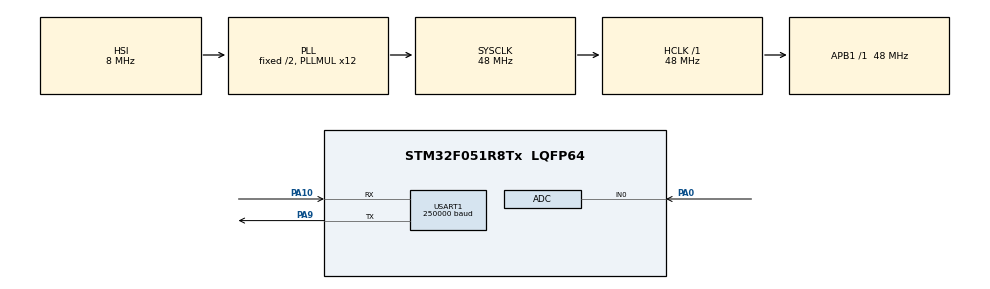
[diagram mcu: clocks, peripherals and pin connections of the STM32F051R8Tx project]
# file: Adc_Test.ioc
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Mcu.Family=STM32F0
Mcu.Name=STM32F051R8Tx
Mcu.Package=LQFP64
PA0.Mode=IN0
PA0.Signal=ADC_IN0
PA10.Mode=Asynchronous
PA10.Signal=USART1_RX
PA9.Mode=Asynchronous
PA9.Signal=USART1_TX
PC14-OSC32_IN.Mode=LSE-External-Oscillator
PC14-OSC32_IN.Signal=RCC_OSC32_IN
PC15-OSC32_OUT.Mode=LSE-External-Oscillator
PC15-OSC32_OUT.Signal=RCC_OSC32_OUT
PF0-OSC_IN.Mode=HSE-External-Oscillator
PF0-OSC_IN.Signal=RCC_OSC_IN
PF1-OSC_OUT.Mode=HSE-External-Oscillator
PF1-OSC_OUT.Signal=RCC_OSC_OUT
ProjectManager.HeapSize=0x200
ProjectManager.StackSize=0x400
ProjectManager.TargetToolchain=STM32CubeIDE
RCC.AHBFreq_Value=48000000
RCC.APB1Freq_Value=48000000
RCC.APB1TimFreq_Value=48000000
RCC.HCLKFreq_Value=48000000
RCC.PLLMUL=RCC_PLL_MUL12
RCC.SYSCLKFreq_VALUE=48000000
RCC.SYSCLKSource=RCC_SYSCLKSOURCE_PLLCLK
USART1.BaudRate=250000
USART1.VirtualMode-Asynchronous=VM_ASYNC
VP_TIM16_VS_ClockSourceINT.Mode=Enable_Timer
board=custom

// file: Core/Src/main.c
/* USER CODE BEGIN Header */
/**
  ******************************************************************************
  * @file           : main.c
  * @brief          : Main program body
  ******************************************************************************
  * @attention
  *
  * Copyright (c) 2023 STMicroelectronics.
  * All rights reserved.
  *
  * This software is licensed under terms that can be found in the LICENSE file
  * in the root directory of this software component.
  * If no LICENSE file comes with this software, it is provided AS-IS.
  *
  ******************************************************************************
  */
/* USER CODE END Header */
#include "main.h"

/* USER CODE BEGIN Includes */
#include <stdio.h>
#include <string.h>
#include "stm32f0xx_hal.h"

/* USER CODE END Includes */

/* USER CODE BEGIN PTD */

uint16_t raw;
char msg[20];
char msg2[15];

volatile uint32_t millis = 0; // Milliseconds counter

#define MAX_READINGS 670 // Maximum number of readings to store

// Structure to store time and ADC value
typedef struct
{
    float time_seconds;
    uint16_t adc_value;
} Reading;

Reading adc_readings[MAX_READINGS]; // Array to store time and ADC readings
uint32_t readings_count = 0; // Number of stored readings

/* USER CODE END PTD */

ADC_HandleTypeDef hadc;

TIM_HandleTypeDef htim16;

UART_HandleTypeDef huart1;

void SystemClock_Config(void);
static void MX_GPIO_Init(void);
static void MX_ADC_Init(void);
static void MX_USART1_UART_Init(void);
static void MX_TIM16_Init(void);

int main(void)
{

  /* MCU Configuration--------------------------------------------------------*/

  /* Reset of all peripherals, Initializes the Flash interface and the Systick. */
  HAL_Init();

  /* Configure the system clock */
  SystemClock_Config();

  /* Initialize all configured peripherals */
  MX_GPIO_Init();
  MX_ADC_Init();
  MX_USART1_UART_Init();
  MX_TIM16_Init();
  /* USER CODE BEGIN 2 */

  HAL_SYSTICK_Config(HAL_RCC_GetHCLKFreq() / 1000); // Configure the SysTick timer for 1ms interrupts

  HAL_TIM_Base_Start_IT(&htim16); // Start TIM16 with interrupts

  /* USER CODE END 2 */

  /* Infinite loop */
  /* USER CODE BEGIN WHILE */
  while (1)
  {

	  // Read ADC value
	  	  	  HAL_ADC_Start(&hadc);
	          HAL_ADC_PollForConversion(&hadc, HAL_MAX_DELAY);
	          uint16_t adc_value = HAL_ADC_GetValue(&hadc);

	          // Calculate time in seconds
	          float time_seconds = (float)(HAL_GetTick()) / 1000.0;

	          // Create a Reading structure and store it in the array
	          if (readings_count < MAX_READINGS)
	          {
	              adc_readings[readings_count].time_seconds = time_seconds;
	              adc_readings[readings_count].adc_value = adc_value;
	              readings_count++;
	          }

	          // Check if we have collected enough readings to transmit
	          if (readings_count >= MAX_READINGS)
	          {
	              // Format and transmit the entire array
	              char uart_data[500]; // Adjust the buffer size as needed
	              int offset = 0;

	              //offset += snprintf(uart_data + offset, sizeof(uart_data) - offset, "Time\tValue\r\n");

	              for (uint32_t i = 0; i < readings_count; i++)
	              {
	                  offset += snprintf(uart_data + offset, sizeof(uart_data) - offset, "%.8f\t%.8f\r\n", adc_readings[i].time_seconds, (float)adc_readings[i].adc_value * 3.3 / 4096.0);
	              }

	              HAL_UART_Transmit(&huart1, (uint8_t *)uart_data, strlen(uart_data), HAL_MAX_DELAY);

	              // Reset the readings_count to collect new readings
	              readings_count = 0;
	          }
    /* USER CODE END WHILE */

  }
}

void SystemClock_Config(void)
{
  RCC_OscInitTypeDef RCC_OscInitStruct = {0};
  RCC_ClkInitTypeDef RCC_ClkInitStruct = {0};
  RCC_PeriphCLKInitTypeDef PeriphClkInit = {0};

  /** Initializes the RCC Oscillators according to the specified parameters
  * in the RCC_OscInitTypeDef structure.
  */
  RCC_OscInitStruct.OscillatorType = RCC_OSCILLATORTYPE_HSI|RCC_OSCILLATORTYPE_HSI14;
  RCC_OscInitStruct.HSIState = RCC_HSI_ON;
  RCC_OscInitStruct.HSI14State = RCC_HSI14_ON;
  RCC_OscInitStruct.HSICalibrationValue = RCC_HSICALIBRATION_DEFAULT;
  RCC_OscInitStruct.HSI14CalibrationValue = 16;
  RCC_OscInitStruct.PLL.PLLState = RCC_PLL_ON;
  RCC_OscInitStruct.PLL.PLLSource = RCC_PLLSOURCE_HSI;
  RCC_OscInitStruct.PLL.PLLMUL = RCC_PLL_MUL12;
  RCC_OscInitStruct.PLL.PREDIV = RCC_PREDIV_DIV1;
  if (HAL_RCC_OscConfig(&RCC_OscInitStruct) != HAL_OK)
  {
    Error_Handler();
  }

  /** Initializes the CPU, AHB and APB buses clocks
  */
  RCC_ClkInitStruct.ClockType = RCC_CLOCKTYPE_HCLK|RCC_CLOCKTYPE_SYSCLK
                              |RCC_CLOCKTYPE_PCLK1;
  RCC_ClkInitStruct.SYSCLKSource = RCC_SYSCLKSOURCE_PLLCLK;
  RCC_ClkInitStruct.AHBCLKDivider = RCC_SYSCLK_DIV1;
  RCC_ClkInitStruct.APB1CLKDivider = RCC_HCLK_DIV1;

  if (HAL_RCC_ClockConfig(&RCC_ClkInitStruct, FLASH_LATENCY_1) != HAL_OK)
  {
    Error_Handler();
  }
  PeriphClkInit.PeriphClockSelection = RCC_PERIPHCLK_USART1;
  PeriphClkInit.Usart1ClockSelection = RCC_USART1CLKSOURCE_PCLK1;
  if (HAL_RCCEx_PeriphCLKConfig(&PeriphClkInit) != HAL_OK)
  {
    Error_Handler();
  }
}

static void MX_ADC_Init(void)
{

  ADC_ChannelConfTypeDef sConfig = {0};

  /** Configure the global features of the ADC (Clock, Resolution, Data Alignment and number of conversion)
  */
  hadc.Instance = ADC1;
  hadc.Init.ClockPrescaler = ADC_CLOCK_ASYNC_DIV1;
  hadc.Init.Resolution = ADC_RESOLUTION_12B;
  hadc.Init.DataAlign = ADC_DATAALIGN_RIGHT;
  hadc.Init.ScanConvMode = ADC_SCAN_DIRECTION_FORWARD;
  hadc.Init.EOCSelection = ADC_EOC_SINGLE_CONV;
  hadc.Init.LowPowerAutoWait = DISABLE;
  hadc.Init.LowPowerAutoPowerOff = DISABLE;
  hadc.Init.ContinuousConvMode = DISABLE;
  hadc.Init.DiscontinuousConvMode = DISABLE;
  hadc.Init.ExternalTrigConv = ADC_SOFTWARE_START;
  hadc.Init.ExternalTrigConvEdge = ADC_EXTERNALTRIGCONVEDGE_NONE;
  hadc.Init.DMAContinuousRequests = DISABLE;
  hadc.Init.Overrun = ADC_OVR_DATA_PRESERVED;
  if (HAL_ADC_Init(&hadc) != HAL_OK)
  {
    Error_Handler();
  }

  /** Configure for the selected ADC regular channel to be converted.
  */
  sConfig.Channel = ADC_CHANNEL_0;
  sConfig.Rank = ADC_RANK_CHANNEL_NUMBER;
  sConfig.SamplingTime = ADC_SAMPLETIME_1CYCLE_5;
  if (HAL_ADC_ConfigChannel(&hadc, &sConfig) != HAL_OK)
  {
    Error_Handler();
  }

}

static void MX_TIM16_Init(void)
{

  htim16.Instance = TIM16;
  htim16.Init.Prescaler = 0;
  htim16.Init.CounterMode = TIM_COUNTERMODE_UP;
  htim16.Init.Period = 65535;
  htim16.Init.ClockDivision = TIM_CLOCKDIVISION_DIV1;
  htim16.Init.RepetitionCounter = 0;
  htim16.Init.AutoReloadPreload = TIM_AUTORELOAD_PRELOAD_DISABLE;
  if (HAL_TIM_Base_Init(&htim16) != HAL_OK)
  {
    Error_Handler();
  }

}

static void MX_USART1_UART_Init(void)
{

  huart1.Instance = USART1;
  huart1.Init.BaudRate = 250000;
  huart1.Init.WordLength = UART_WORDLENGTH_8B;
  huart1.Init.StopBits = UART_STOPBITS_1;
  huart1.Init.Parity = UART_PARITY_NONE;
  huart1.Init.Mode = UART_MODE_TX_RX;
  huart1.Init.HwFlowCtl = UART_HWCONTROL_NONE;
  huart1.Init.OverSampling = UART_OVERSAMPLING_16;
  huart1.Init.OneBitSampling = UART_ONE_BIT_SAMPLE_DISABLE;
  huart1.AdvancedInit.AdvFeatureInit = UART_ADVFEATURE_NO_INIT;
  if (HAL_UART_Init(&huart1) != HAL_OK)
  {
    Error_Handler();
  }

}

static void MX_GPIO_Init(void)
{

  /* GPIO Ports Clock Enable */
  __HAL_RCC_GPIOC_CLK_ENABLE();
  __HAL_RCC_GPIOF_CLK_ENABLE();
  __HAL_RCC_GPIOA_CLK_ENABLE();

}

/* USER CODE BEGIN 4 */
void HAL_TIM_PeriodElapsedCallback(TIM_HandleTypeDef *htim)
{
  if (htim == &htim16)
  {
    millis++; // Increment the milliseconds counter
  }
}
/* USER CODE END 4 */

void Error_Handler(void)
{
  __disable_irq();
  while (1)
  {
  }
}
